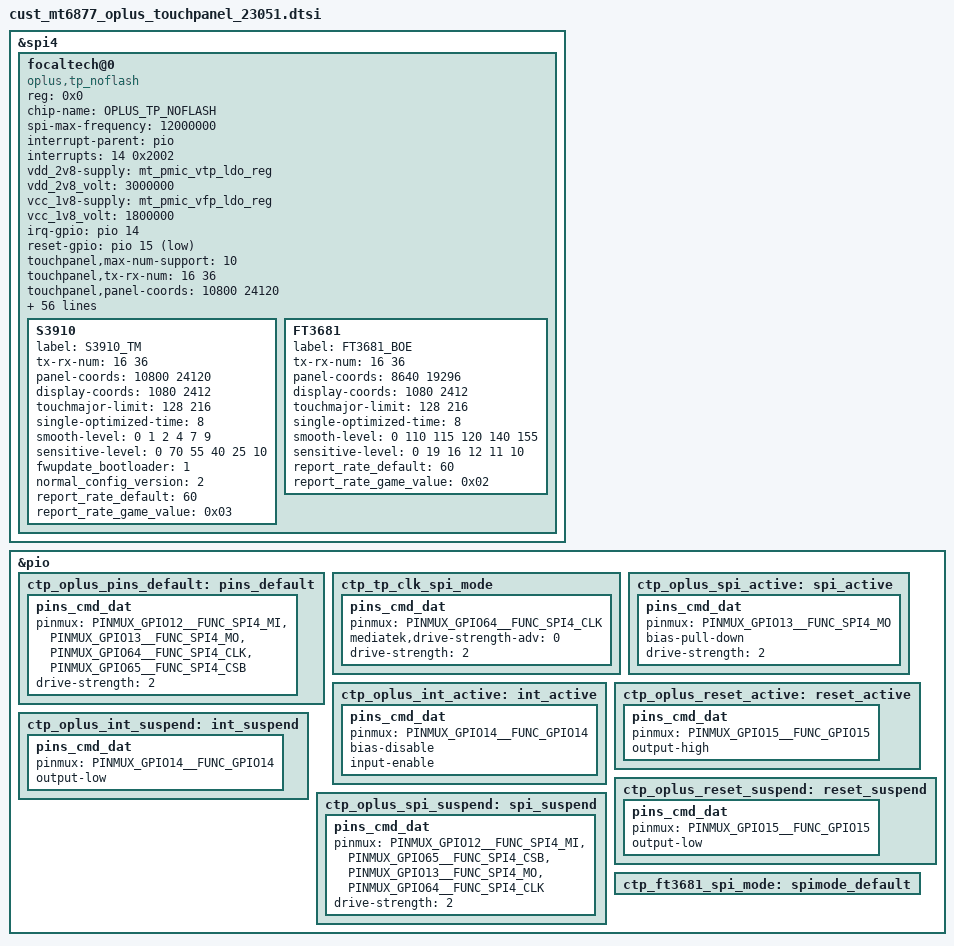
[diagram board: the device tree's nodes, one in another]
// SPDX-License-Identifier: GPL-2.0
/*
 * Copyright (c) 2021 MediaTek Inc.
 */

&spi4 {
	status = "okay";
	#address-cells = <1>;
	#size-cells = <0>;




	focaltech@0{
		compatible = "oplus,tp_noflash";
		reg = <0x0>;
		chip-name = "OPLUS_TP_NOFLASH";
		status = "okay";
		spi-max-frequency = <12000000>;
		/* Interrupt && Irq-gpio */
		interrupt-parent = <&pio>;
		interrupts = <14 0x2002>;

		/* Power Config */

		vdd_2v8-supply  = <&mt_pmic_vtp_ldo_reg>;
		vdd_2v8_volt = <3000000>;
		vcc_1v8-supply  = <&mt_pmic_vfp_ldo_reg>;
		vcc_1v8_volt = <1800000>;


		/* Other HW Resource */

		irq-gpio = <&pio 14 0x2002>;
		reset-gpio = <&pio 15 0x1>;

		touchpanel,max-num-support = <10>;
		touchpanel,tx-rx-num = <16 36>;
		touchpanel,panel-coords = <10800 24120>;
		touchpanel,display-coords = <1080 2412>;
		touchpanel,touchmajor-limit = <128 216>;
		touchpanel,elimination-range = <20 200 200>;
		//touchpanel,int-mode = <1>; /*0: interrupt and disable, 1:interrupt and not disable*/
		touchpanel,smooth-level = <0 110 115 120 140 155>;
		touchpanel,smooth-level-charging = <0 110 115 120 140 155>;
		touchpanel,sensitive-level = <0 19 16 12 11 10>;
		touchpanel,tp-index = <0>;
		touchpanel,high-frame-rate-time = <60>;
		disable_suspend_irq_handler_support;

		vid_len = <2>;
		tp_type = <7>; /* panel-VXN*/
		platform_support_project = <23051 23241 23243>;
		platform_support_project_dir = <23051 23051 23051>;
		platform_support_project_commandline = "default_commandline","default_commandline","default_commandline";


		/* SW Support Feature Control */
		//headset_pump_support;
		health_monitor_v2_support;
		black_gesture_support;
		charger_pump_support;
		//lcd_tp_refresh_support;
		fw_update_app_support;
		smart_gesture_support;
		game_switch_support;
		report_flow_unlock_support;
		//kernel_grip_support;
		fw_edge_limit_support;
		fingerprint_underscreen_support;
		freq_hop_simulate_support;
		pressure_report_support;
		touchpanel,single-optimized-time = <8>;
		report_rate_white_list_support;
		auto_test_force_pass_support;
		snr_read_support;
		//high_resolution_support;
		screenoff_fingerprint_info_support;
		irq_need_dev_resume_ok;
		sportify_aod_gesture_support;
		black_gesture_indep_support;
		thermal_detect_support;
		exception_upload_support;
		tp_data_record_support;
		//enable_point_auto_change;
		palm_to_sleep_support;

		/*
		 *Virtual Key Config:
		 *1:touchpanel,button-type: <virtualkey_type  supportted_button-map>
		 *virtualkey_type:
		 *Type 1: using board_properties
		 *Type 2: using same IC (button zone&& touch zone are seprate)
		 *Type 3: using diffrent IC (button zone&& touch zone are seprate)
		 *Type 4: No need of virtual key process
		 *supportted_button-map:select|menu|home|back
		 *
		 *2:touchpanel,button-map
		 *type (X1,Y1)(X2,Y2)(X3,Y3)(Width_X,Hight_Y)--Only when button-type is 0
		 */
		touchpanel,button-type = <4>;
		touchpanel.button-TRx = <0 0>;

		pinctrl-names = "default",  "oplus_int_active",
		"oplus_reset_active", "oplus_int_suspend",
		"oplus_reset_suspend", "oplus_spi_active",
		"oplus_spi_suspend", "pin_set_high",
		"pin_set_low";
	pinctrl-0 = <&ctp_oplus_pins_default &ctp_tp_clk_spi_mode>;
	pinctrl-1 = <&ctp_oplus_int_active>;
	pinctrl-2 = <&ctp_oplus_reset_active>;
	pinctrl-3 = <&ctp_oplus_int_suspend>;
	pinctrl-4 = <&ctp_oplus_reset_suspend>;
	pinctrl-5 = <&ctp_oplus_spi_active>;
	pinctrl-6 = <&ctp_oplus_spi_suspend>;
	pinctrl-7 = <&ctp_oplus_int_active &ctp_oplus_reset_active &ctp_oplus_spi_active>;
	pinctrl-8 = <&ctp_oplus_int_suspend &ctp_oplus_reset_suspend &ctp_oplus_spi_suspend>;

		S3910 {
			label = "S3910_TM";
			tx-rx-num = <16 36>;
			panel-coords = <10800 24120>;
			display-coords = <1080 2412>;
			touchmajor-limit = <128 216>;
			single-optimized-time = <8>;
			smooth-level = <0 1 2 4 7 9>;
			sensitive-level = <0 70 55 40 25 10>;
			fwupdate_bootloader = <1>;
			normal_config_version = <2>;
			report_rate_default = <60>;
			report_rate_game_value = <0x03>;
			//fps_report_rate = <60 2 90 3 120 3>;//1:360Hz 2:120Hz 3:240Hz
		};
		FT3681 {
			label = "FT3681_BOE";
			tx-rx-num = <16 36>;
			panel-coords = <8640 19296>;
			display-coords = <1080 2412>;
			touchmajor-limit = <128 216>;
			single-optimized-time = <8>;
			smooth-level = <0 110 115 120 140 155>;
			sensitive-level = <0 19 16 12 11 10>;
			report_rate_default = <60>;
			report_rate_game_value = <0x02>;
		};

	};
};


&pio {
	ctp_oplus_pins_default: pins_default {
		pins_cmd_dat {
			pinmux = <PINMUX_GPIO12__FUNC_SPI4_MI>,
				<PINMUX_GPIO13__FUNC_SPI4_MO>,
				<PINMUX_GPIO64__FUNC_SPI4_CLK>,
				<PINMUX_GPIO65__FUNC_SPI4_CSB>;
			drive-strength = <2>;
		};
	};
	ctp_tp_clk_spi_mode:ctp_tp_clk_spi_mode{
		pins_cmd_dat {
			pinmux = <PINMUX_GPIO64__FUNC_SPI4_CLK>;
			mediatek,drive-strength-adv = <0>;/*EH[2:0]*/
			drive-strength = <2>;
		};
	};
	ctp_oplus_spi_active:spi_active{
		pins_cmd_dat {
			pinmux = <PINMUX_GPIO13__FUNC_SPI4_MO>;
			bias-pull-down;
			drive-strength = <2>;
		};
	};
	ctp_oplus_int_active: int_active {
		pins_cmd_dat {
			pinmux = <PINMUX_GPIO14__FUNC_GPIO14>;
			bias-disable;
			input-enable;
		};
	};
	ctp_oplus_reset_active: reset_active {
		pins_cmd_dat {
			pinmux = <PINMUX_GPIO15__FUNC_GPIO15>;
			output-high;
		};
	};
	ctp_oplus_int_suspend: int_suspend {
		pins_cmd_dat {
			pinmux = <PINMUX_GPIO14__FUNC_GPIO14>;
			output-low;
		};
	};
	ctp_oplus_reset_suspend: reset_suspend {
		pins_cmd_dat {
			pinmux = <PINMUX_GPIO15__FUNC_GPIO15>;
			output-low;
		};
	};
	ctp_oplus_spi_suspend:spi_suspend{
		pins_cmd_dat {
			pinmux = <PINMUX_GPIO12__FUNC_SPI4_MI>,
				<PINMUX_GPIO65__FUNC_SPI4_CSB>,
				<PINMUX_GPIO13__FUNC_SPI4_MO>,
				<PINMUX_GPIO64__FUNC_SPI4_CLK>;
			drive-strength = <2>;
		};
	};
	ctp_ft3681_spi_mode: spimode_default {
	};
};

/*End of this file, DO NOT ADD ANYTHING HERE*/

